# earlgrey register map
Vendor: lowRISC; File version: 0.1
CPU: ibex rev01, little endian, no MPU, no FPU, VTOR, 2 interrupt priority bits, 2 interrupts
Registers are 32-bit, read-write, no defined reset value unless marked. A register's access mark holds for its fields unless they carry their own. Offsets are from the block's base; [hi:lo] are bit positions.

## EDN0 — Distributes random numbers produced by CSRNG to hardware blocks
Base 0x41170000
Same registers: EDN1 0x41180000
0x40 REGWEN — Register write enable for all control registers
  [0] Value — When true, the CTRL can be written by software.When false, this field read-only. Defaults true, write zero to clear.Note that this needs to be cleared after initial configuration at boot in order tolock in the listed register settings.
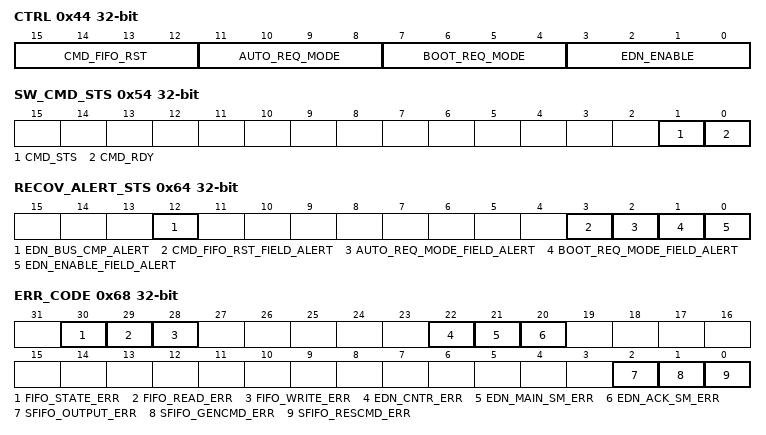
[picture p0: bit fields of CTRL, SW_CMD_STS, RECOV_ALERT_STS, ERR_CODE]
0x44 CTRL — EDN control register
  [15:12] CMD_FIFO_RST — Setting this field to kMultiBitBool4True clears the two command FIFOs: theRESEED_CMD FIFO and the GENERATE_CMD FIFO. This field must beset to the reset state by software before any further commands can be issued tothese FIFOs.
  [11:8] AUTO_REQ_MODE — Setting this field to kMultiBitBool4True will enable the EDN block to automaticallysend another request to CSRNG application interface. It is assumed that a CSRNGinstantiate command will be issued using the !!SW_CMD_REQ register interface.When this command has an command ack returned from CSRNG, anew generate command will be send out again without software intervention. It isexpected that the generate command will be sent repeatedly so that a continuoussupply of entropy can be delivered to the endpoints. Reseed commands will be senton a programmable basic between generate commands.The !!GENERATE_CMD, !!RESEED_CMD, and !!MAX_NUM_REQS_BETWEEN_RESEEDS registers mustset up before the !!SW_CMD_REQ register command is issued.
  [7:4] BOOT_REQ_MODE — Setting this field to kMultiBitBool4True will enable the feature where the EDN blockwill automatically send a boot-time request to the CSRNG application interface.The purpose of this feature is to request entropy as fast as possible after reset,and during chip boot-time.
  [3:0] EDN_ENABLE — Setting this field to kMultiBitBool4True enables the EDN module. The modules of theentropy complex may only be enabled and disabled in a specific order, seeProgrammers Guide for details.
0x48 BOOT_INS_CMD — EDN boot instantiate command register
  [31:0] BOOT_INS_CMD — This field is used as the value for Instantiate command at boot time.
0x4C BOOT_GEN_CMD — EDN boot generate command register
  [31:0] BOOT_GEN_CMD — This field is used as the value for generate command at boot time.
0x50 SW_CMD_REQ wo — EDN csrng app command request register
  [31:0] SW_CMD_REQ — Any CSRNG action can be initiated by writing a CSRNG command to thisregister. The application interface must wait for the "ack" toreturn before issuing new commands. This interface is intendedto be controlled solely by software.If !!CTRL.AUTO_REQ_MODE is set, only the first instantiate command has anyeffect. After that command has been processed, writes to this registerregister will have no effect on operation.Note that CSRNG command format details can be foundin the CSRNG documentation.
0x54 SW_CMD_STS ro — EDN command status register
  [1] CMD_STS — This one bit field is the status code returned with the application command ack.It is updated each time a command ack is asserted on the CSRNG interface.0b0: Request completed successfully0b1: Request completed with an error
  [0] CMD_RDY — This bit indicates when the command interface is ready to accept commands.
0x58 RESEED_CMD wo — EDN csrng reseed command register
  [31:0] RESEED_CMD — Writing this register will fill a FIFO with up to 13 command words (32b words).This FIFO will be used to automatically send out a reseed command to the CSRNGapplication interface when in !!CTRL.AUTO_REQ_MODE. This command will be sent only afterthe MAX_NUM_REQS_BETWEEN_RESEEDS counter value has reached zero.If more than 13 entires are written to the FIFO, the design will automatically generatea fatal alert.Note that CSRNG command format details can be foundin the CSRNG documentation.
0x5C GENERATE_CMD wo — EDN csrng generate command register
  [31:0] GENERATE_CMD — Writing this register will fill a FIFO with up to 13 command words (32b words).This FIFO will be used to automatically send out a generate command to the CSRNGappl interface when in !!CTRL.AUTO_REQ_MODE. This command will be sent only afterreceiving a command ack from the previous command.If more than 13 entires are written to the FIFO, the design will automatically generatea fatal alert.Note that CSRNG command format details can be foundin the CSRNG documentation.
0x60 MAX_NUM_REQS_BETWEEN_RESEEDS — EDN maximum number of requests between reseeds register
  [31:0] MAX_NUM_REQS_BETWEEN_RESEEDS — Setting this field will set the number of generate requests that can be madeto CSRNG before a reseed request is made. This value only has meaning when in!!CTRL.AUTO_REQ_MODE. This register supports a maximum of 2^32 requests between reseeds.This register will be used by a counter that counts down, triggering anautomatic reseed when it reaches zero.
0x64 RECOV_ALERT_STS — Recoverable alert status register
  [12] EDN_BUS_CMP_ALERT — This bit is set when the interal entropy bus value is equal to the priorvalid value on the bus, indicating a possible attack.Writing a zero resets this status bit.
  [3] CMD_FIFO_RST_FIELD_ALERT — This bit is set when the CMD_FIFO_RST field is set to an illegal value,something other than kMultiBitBool4True or kMultiBitBool4False.Writing a zero resets this status bit.
  [2] AUTO_REQ_MODE_FIELD_ALERT — This bit is set when the !!CTRL.AUTO_REQ_MODE field is set to an illegal value,something other than kMultiBitBool4True or kMultiBitBool4False.Writing a zero resets this status bit.
  [1] BOOT_REQ_MODE_FIELD_ALERT — This bit is set when the BOOT_REQ_MODE field is set to an illegal value,something other than kMultiBitBool4True or kMultiBitBool4False.Writing a zero resets this status bit.
  [0] EDN_ENABLE_FIELD_ALERT — This bit is set when the EDN_ENABLE field is set to an illegal value,something other than kMultiBitBool4True or kMultiBitBool4False.Writing a zero resets this status bit.
0x68 ERR_CODE ro — Hardware detection of fatal error conditions status register
  [30] FIFO_STATE_ERR — This bit will be set to one when any of the source bits (bits 0 through 1 of thisthis register) are asserted as a result of an error pulse generated fromany FIFO where both the empty and full status bits are set.This bit will stay set until the next reset.
  [29] FIFO_READ_ERR — This bit will be set to one when any of the source bits (bits 0 through 1 of thisthis register) are asserted as a result of an error pulse generated fromany empty FIFO that has recieved a read pulse.This bit will stay set until the next reset.
  [28] FIFO_WRITE_ERR — This bit will be set to one when any of the source bits (bits 0 through 1 of thisthis register) are asserted as a result of an error pulse generated fromany full FIFO that has been recieved a write pulse.This bit will stay set until the next reset.
  [22] EDN_CNTR_ERR — This bit will be set to one when a hardened counter has detected an errorcondition. This error will signal a fatal alert.This bit will stay set until the next reset.
  [21] EDN_MAIN_SM_ERR — This bit will be set to one when an illegal state has been detected for theEDN main stage state machine. This error will signal a fatal alert.This bit will stay set until the next reset.
  [20] EDN_ACK_SM_ERR — This bit will be set to one when an illegal state has been detected for theEDN ack stage state machine. This error will signal a fatal alert.This bit will stay set until the next reset.
  [2] SFIFO_OUTPUT_ERR — This bit will be set to one when an error has been detected for theoutput FIFO. The type of error is reflected in the type statusbits (bits 28 through 30 of this register).When this bit is set, a fatal error condition will result.
  [1] SFIFO_GENCMD_ERR — This bit will be set to one when an error has been detected for thegenerate command FIFO. The type of error is reflected in the type statusbits (bits 28 through 30 of this register).When this bit is set, a fatal error condition will result.This bit will stay set until the next reset.
  [0] SFIFO_RESCMD_ERR — This bit will be set to one when an error has been detected for thereseed command FIFO. The type of error is reflected in the type statusbits (bits 28 through 30 of this register).When this bit is set, a fatal error condition will result.
0x6C ERR_CODE_TEST — Test error conditions register
  [4:0] ERR_CODE_TEST — Setting this field will set the bit number for which an errorwill be forced in the hardware. This bit number is that same onefound in the !!ERR_CODE register. The action of writing thisregister will force an error pulse. The sole purpose of thisregister is to test that any error properly propagates to eitheran interrupt or an alert.
0x70 MAIN_SM_STATE ro — Main state machine state observation register
  [8:0] MAIN_SM_STATE — This is the state of the EDN main state machine.See the RTL file `edn_main_sm` for the meaning of the values.
